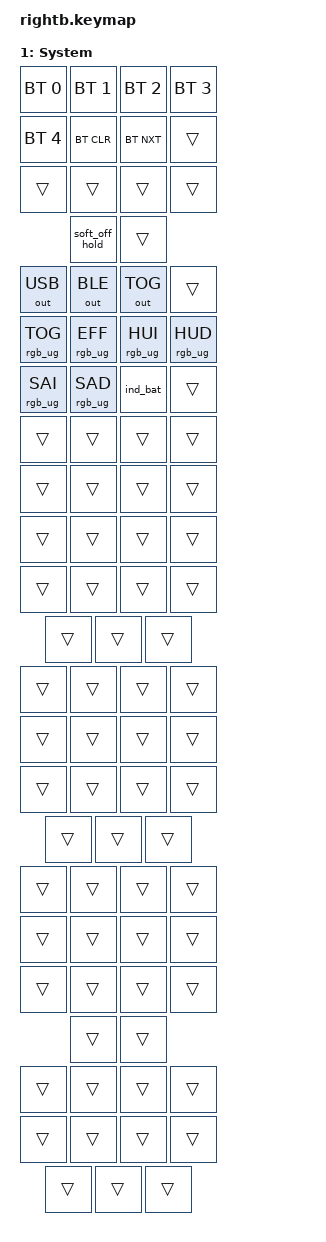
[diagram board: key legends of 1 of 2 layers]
// This file was generated from a template. Edit it to match your keyboard.
// See https://zmk.dev/docs/development/hardware-integration/new-shield for more instructions.

#include <behaviors.dtsi>
#include <behaviors/rgbled_widget.dtsi>
#include <dt-bindings/zmk/keys.h>
#include <dt-bindings/zmk/bt.h>
#include <dt-bindings/zmk/outputs.h>
#include <dt-bindings/zmk/rgb.h>

/ {
    // Define a default keymap here.
    // See https://zmk.dev/docs/development/hardware-integration/new-shield#default-keymap.

    behaviors {
        rgb_encoder: rgb_encoder {
            compatible = "zmk,behavior-sensor-rotate";
            #sensor-binding-cells = <0>;
            bindings = <&rgb_ug RGB_BRD>, <&rgb_ug RGB_BRI>;
        };

        soft_off_hold: soft_off_hold {
            compatible = "zmk,behavior-soft-off";
            #binding-cells = <0>;
            hold-time-ms = <3000>;
        };
    };

    keymap {
        compatible = "zmk,keymap";

        default_layer {
            display-name = "Base";

            bindings = <
                /* Esc F1 F2 F3 F4 F5 F8 F9 F10 F11 F12 PrtSc Delete Encoder */
                &kp ESC     &kp F1      &kp F2      &kp F3
                &kp F4      &kp F5      &kp F8      &kp F9
                &kp F10     &kp F11     &kp F12     &kp PSCRN
                &kp DEL     &kp C_MUTE

                /* ` 1 2 3 4 F6 F7 8 9 0 - = Backspace Home */
                &kp GRAVE   &kp N1      &kp N2      &kp N3
                &kp N4      &kp F6      &kp F7      &kp N8
                &kp N9      &kp N0      &kp MINUS   &kp EQUAL
                &kp BSPC    &kp HOME

                /* Tab Q W E R 5 7 U I O P [ ] \ End */
                &kp TAB     &kp Q       &kp W       &kp E
                &kp R       &kp N5      &kp N7      &kp U
                &kp I       &kp O       &kp P       &kp LBKT
                &kp RBKT    &kp BSLH    &kp END

                /* LCtrl A S D F 6 Y K L ; ' Enter Up */
                &kp LCTRL   &kp A       &kp S       &kp D
                &kp F       &kp N6      &kp Y       &kp K
                &kp L       &kp SEMI    &kp SQT     &kp ENTER
                &kp UP

                /* LShift Z X C V T H J M , . / RShift Down */
                &kp LSHFT   &kp Z       &kp X       &kp C
                &kp V       &kp T       &kp H       &kp J
                &kp M       &kp COMMA   &kp DOT     &kp FSLH
                &kp RSHFT   &kp DOWN

                /* Enter LGui LAlt LSpace G Y B N RSpace Fn1 Fn2 Left Right */
                &kp ENTER   &kp LGUI    &kp LALT    &kp SPACE
                &kp G       &kp Y       &kp B       &kp N
                &kp SPACE   &mo 1       &studio_unlock
                &kp LEFT    &kp RIGHT
            >;

            sensor-bindings = <&inc_dec_kp C_VOL_DN C_VOL_UP>;
        };

        layer1 {
            display-name = "System";

            bindings = <
                /* Esc F1 F2 F3 F4 F5 F8 F9 F10 F11 F12 PrtSc Delete Encoder */
                &bt BT_SEL 0  &bt BT_SEL 1  &bt BT_SEL 2  &bt BT_SEL 3
                &bt BT_SEL 4  &bt BT_CLR    &bt BT_NXT    &trans
                &trans        &trans        &trans        &trans
                &soft_off_hold  &trans

                /* ` 1 2 3 4 F6 F7 8 9 0 - = Backspace Home */
                &out OUT_USB      &out OUT_BLE      &out OUT_TOG      &trans
                &rgb_ug RGB_TOG   &rgb_ug RGB_EFF   &rgb_ug RGB_HUI   &rgb_ug RGB_HUD
                &rgb_ug RGB_SAI   &rgb_ug RGB_SAD   &ind_bat          &trans
                &trans            &trans            &trans            &trans

                /* Tab Q W E R 5 7 U I O P [ ] \ End */
                &trans &trans &trans &trans
                &trans &trans &trans &trans
                &trans &trans &trans &trans
                &trans &trans &trans

                /* LCtrl A S D F 6 Y K L ; ' Enter Up */
                &trans &trans &trans &trans
                &trans &trans &trans &trans
                &trans &trans &trans &trans
                &trans &trans &trans

                /* LShift Z X C V T H J M , . / RShift Down */
                &trans &trans &trans &trans
                &trans &trans &trans &trans
                &trans &trans &trans &trans
                &trans &trans

                /* LCtrl LGui LAlt LSpace G Y B N RSpace Fn1 Fn2 Left Right */
                &trans &trans &trans &trans
                &trans &trans &trans &trans
                &trans &trans &trans
            >;

            sensor-bindings = <&rgb_encoder>;
        };

        extra2 {
            status = "reserved";
        };
    };
};
